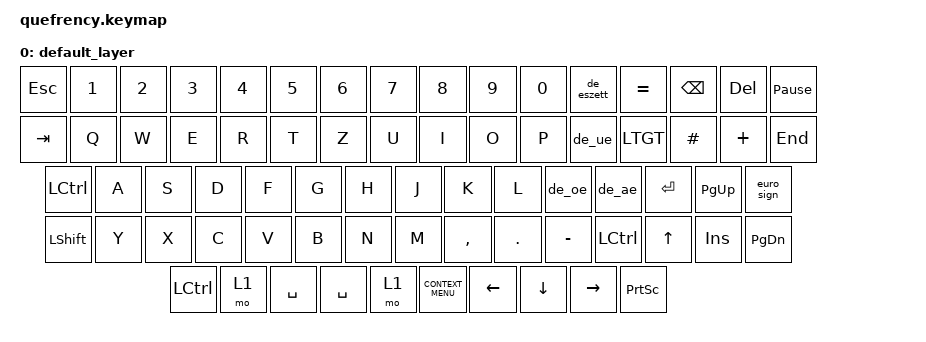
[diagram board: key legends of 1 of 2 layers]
#include "helper.h"
#include "34.h"

#define ___ &trans

/ {
    keymap {
        compatible = "zmk,keymap";

        default_layer {
            bindings = <
                &kp ESC &kp N1 &kp N2 &kp N3 &kp N4 &kp N5 &kp N6 &kp N7 &kp N8 &kp N9 &kp N0 &de_eszett &kp EQUAL &kp BSPC &kp DEL &kp PAUSE_BREAK
                &kp TAB &kp Q &kp W &kp E &kp R &kp T &kp Z &kp U &kp I &kp O &kp P &de_ue &kp LTGT &kp HASH &kp PLUS &kp END
                &kp LCTRL &kp A &kp S &kp D &kp F &kp G &kp H &kp J &kp K &kp L &de_oe &de_ae &kp RET &kp PG_UP &euro_sign
                &kp LSHFT &kp Y &kp X &kp C &kp V &kp B &kp N &kp M &kp COMMA &kp DOT &kp MINUS &kp LCTRL &kp UP &kp INSERT &kp PG_DN
                &kp LCTRL &mo 1 &kp SPACE &kp SPACE &mo 1 &kp K_CONTEXT_MENU &kp LEFT &kp DOWN &kp RIGHT &kp PSCRN
            >;
        };

        fn_layer {
            bindings = <
                &bt BT_CLR &kp F1 &kp F2 &kp F3 &kp F4 &kp F5 &kp F6 &kp F7 &kp F8 &kp F9 &kp F10 &kp F11 &kp F12 &trans &bt BT_CLR
                &trans &bt BT_SEL 0 &bt BT_SEL 1 &bt BT_SEL 2 &trans &trans &trans &trans &trans &trans &trans &trans &trans &trans &trans
                &trans &trans &trans &trans &trans &trans &trans &trans &trans &trans &trans &trans &trans &trans &trans
                &trans &trans &trans &trans &trans &trans &trans &trans &trans &trans &trans &trans &trans &trans &trans
                &trans &trans &trans &trans &trans &trans &trans &trans &trans &trans
            >;
        };
    };
};
